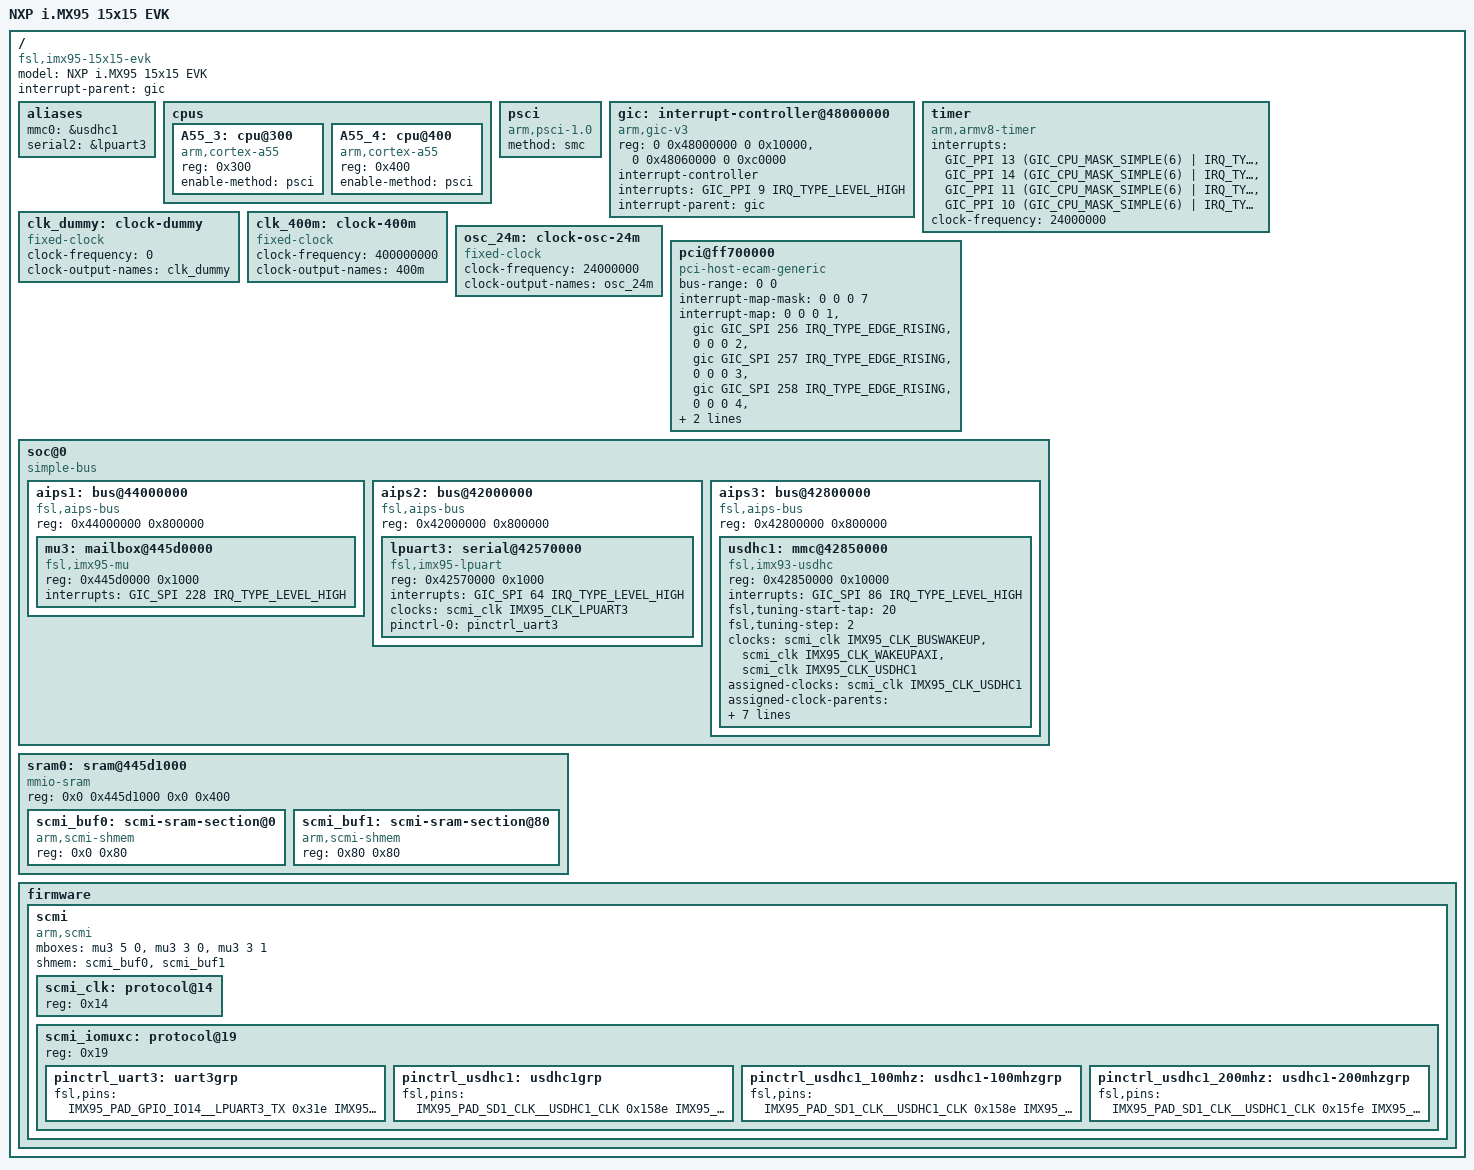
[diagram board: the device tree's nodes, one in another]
// SPDX-License-Identifier: (GPL-2.0+ OR MIT)
/*
 * Copyright 2024 NXP
 */

/dts-v1/;

#include <dt-bindings/clock/fsl,imx95-clock.h>
#include <dt-bindings/interrupt-controller/arm-gic.h>
#include "imx95-pinfunc.h"

/ {
	model = "NXP i.MX95 15x15 EVK";
	compatible = "fsl,imx95-15x15-evk", "fsl,imx95";
	interrupt-parent = <&gic>;
	#address-cells = <2>;
	#size-cells = <2>;

	aliases {
		mmc0 = &usdhc1;
		serial2 = &lpuart3;
	};

	cpus {
		#address-cells = <1>;
		#size-cells = <0>;

		A55_3: cpu@300 {
			device_type = "cpu";
			compatible = "arm,cortex-a55";
			reg = <0x300>;
			enable-method = "psci";
			#cooling-cells = <2>;
		};

		A55_4: cpu@400 {
			device_type = "cpu";
			compatible = "arm,cortex-a55";
			reg = <0x400>;
			enable-method = "psci";
			#cooling-cells = <2>;
		};
	};

	psci {
		compatible = "arm,psci-1.0";
		method = "smc";
	};

	gic: interrupt-controller@48000000 {
		compatible = "arm,gic-v3";
		reg = <0 0x48000000 0 0x10000>,
		      <0 0x48060000 0 0xc0000>;
		#interrupt-cells = <3>;
		interrupt-controller;
		interrupts = <GIC_PPI 9 IRQ_TYPE_LEVEL_HIGH>;
		interrupt-parent = <&gic>;
	};

	timer {
		compatible = "arm,armv8-timer";
		interrupts = <GIC_PPI 13 (GIC_CPU_MASK_SIMPLE(6) | IRQ_TYPE_LEVEL_LOW)>,
			     <GIC_PPI 14 (GIC_CPU_MASK_SIMPLE(6) | IRQ_TYPE_LEVEL_LOW)>,
			     <GIC_PPI 11 (GIC_CPU_MASK_SIMPLE(6) | IRQ_TYPE_LEVEL_LOW)>,
			     <GIC_PPI 10 (GIC_CPU_MASK_SIMPLE(6) | IRQ_TYPE_LEVEL_LOW)>;
		clock-frequency = <24000000>;
	};

	clk_dummy: clock-dummy {
		compatible = "fixed-clock";
		#clock-cells = <0>;
		clock-frequency = <0>;
		clock-output-names = "clk_dummy";
	};

	clk_400m: clock-400m {
		compatible = "fixed-clock";
		#clock-cells = <0>;
		clock-frequency = <400000000>;
		clock-output-names = "400m";
	};

	osc_24m: clock-osc-24m {
		compatible = "fixed-clock";
		#clock-cells = <0>;
		clock-frequency = <24000000>;
		clock-output-names = "osc_24m";
	};

	pci@ff700000 {
		compatible = "pci-host-ecam-generic";
		device_type = "pci";
		bus-range = <0 0>;
		#address-cells = <3>;
		#size-cells = <2>;
		#interrupt-cells = <1>;
		interrupt-map-mask = <0 0 0 7>;
		interrupt-map = <0 0 0 1 &gic GIC_SPI 256 IRQ_TYPE_EDGE_RISING>,
				<0 0 0 2 &gic GIC_SPI 257 IRQ_TYPE_EDGE_RISING>,
				<0 0 0 3 &gic GIC_SPI 258 IRQ_TYPE_EDGE_RISING>,
				<0 0 0 4 &gic GIC_SPI 259 IRQ_TYPE_EDGE_RISING>;
		reg = <0x0 0xff700000 0x0 0x100000>;
		ranges = <0x02000000 0x00 0x10000000 0x0 0x10000000 0x00 0x10000>;
	};

	soc@0 {
		compatible = "simple-bus";
		#address-cells = <1>;
		#size-cells = <1>;
		ranges = <0x0 0x0 0x0 0x80000000>,
			 <0x28000000 0x0 0x28000000 0x10000000>;

		aips1: bus@44000000 {
			compatible = "fsl,aips-bus", "simple-bus";
			reg = <0x44000000 0x800000>;
			#address-cells = <1>;
			#size-cells = <1>;
			ranges;

			mu3: mailbox@445d0000 {
				compatible = "fsl,imx95-mu", "fsl,imx8ulp-mu";
				reg = <0x445d0000 0x1000>;
				interrupts = <GIC_SPI 228 IRQ_TYPE_LEVEL_HIGH>;
				#mbox-cells = <2>;
				status = "okay";
			};
		};

		aips2: bus@42000000 {
			compatible = "fsl,aips-bus", "simple-bus";
			reg = <0x42000000 0x800000>;
			#address-cells = <1>;
			#size-cells = <1>;
			ranges;

			lpuart3: serial@42570000 {
				compatible = "fsl,imx95-lpuart", "fsl,imx8ulp-lpuart",
					     "fsl,imx7ulp-lpuart";
				reg = <0x42570000 0x1000>;
				interrupts = <GIC_SPI 64 IRQ_TYPE_LEVEL_HIGH>;
				clock-names = "ipg";
				status = "disabled";
			};
		};

		aips3: bus@42800000 {
			compatible = "fsl,aips-bus", "simple-bus";
			reg = <0x42800000 0x800000>;
			#address-cells = <1>;
			#size-cells = <1>;
			ranges;

			usdhc1: mmc@42850000 {
				compatible = "fsl,imx93-usdhc", "fsl,imx8mm-usdhc";
				reg = <0x42850000 0x10000>;
				interrupts = <GIC_SPI 86 IRQ_TYPE_LEVEL_HIGH>;
				fsl,tuning-start-tap = <20>;
				fsl,tuning-step= <2>;
				status = "disabled";
			};
		};
	};

	sram0: sram@445d1000 {
		compatible = "mmio-sram";
		reg = <0x0 0x445d1000 0x0 0x400>;
		#address-cells = <1>;
		#size-cells = <1>;
		ranges = <0x0 0x0 0x445d1000 0x400>;

		scmi_buf0: scmi-sram-section@0 {
			compatible = "arm,scmi-shmem";
			reg = <0x0 0x80>;
		};

		scmi_buf1: scmi-sram-section@80 {
			compatible = "arm,scmi-shmem";
			reg = <0x80 0x80>;
		};
	};

	firmware {
		scmi {
			compatible = "arm,scmi";
			mboxes = <&mu3 5 0>, <&mu3 3 0>, <&mu3 3 1>;
			shmem = <&scmi_buf0>, <&scmi_buf1>;
			#address-cells = <1>;
			#size-cells = <0>;

			scmi_clk: protocol@14 {
				reg = <0x14>;
				#clock-cells = <1>;
			};

			scmi_iomuxc: protocol@19 {
				reg = <0x19>;
			};
		};
	};
};

&lpuart3 {
	clocks = <&scmi_clk IMX95_CLK_LPUART3>;
	pinctrl-names = "default";
	pinctrl-0 = <&pinctrl_uart3>;
	status = "okay";
};

&usdhc1 {
	clocks = <&scmi_clk IMX95_CLK_BUSWAKEUP>,
		 <&scmi_clk IMX95_CLK_WAKEUPAXI>,
		 <&scmi_clk IMX95_CLK_USDHC1>;
	clock-names = "ipg", "ahb", "per";
	assigned-clocks = <&scmi_clk IMX95_CLK_USDHC1>;
	assigned-clock-parents = <&scmi_clk IMX95_CLK_SYSPLL1_PFD1>;
	assigned-clock-rates = <400000000>;
	pinctrl-names = "default", "state_100mhz", "state_200mhz";
	pinctrl-0 = <&pinctrl_usdhc1>;
	pinctrl-1 = <&pinctrl_usdhc1_100mhz>;
	pinctrl-2 = <&pinctrl_usdhc1_200mhz>;
	bus-width = <8>;
	non-removable;
	status = "okay";
};

&scmi_iomuxc {
	pinctrl_uart3: uart3grp {
		fsl,pins = <
			IMX95_PAD_GPIO_IO14__LPUART3_TX      0x31e
			IMX95_PAD_GPIO_IO15__LPUART3_RX      0x31e
		>;
	};

	pinctrl_usdhc1: usdhc1grp {
		fsl,pins = <
			IMX95_PAD_SD1_CLK__USDHC1_CLK				0x158e
			IMX95_PAD_SD1_CMD__USDHC1_CMD				0x138e
			IMX95_PAD_SD1_DATA0__USDHC1_DATA0			0x138e
			IMX95_PAD_SD1_DATA1__USDHC1_DATA1			0x138e
			IMX95_PAD_SD1_DATA2__USDHC1_DATA2			0x138e
			IMX95_PAD_SD1_DATA3__USDHC1_DATA3			0x138e
			IMX95_PAD_SD1_DATA4__USDHC1_DATA4			0x138e
			IMX95_PAD_SD1_DATA5__USDHC1_DATA5			0x138e
			IMX95_PAD_SD1_DATA6__USDHC1_DATA6			0x138e
			IMX95_PAD_SD1_DATA7__USDHC1_DATA7			0x138e
			IMX95_PAD_SD1_STROBE__USDHC1_STROBE			0x158e
		>;
	};

	pinctrl_usdhc1_100mhz: usdhc1-100mhzgrp {
		fsl,pins = <
			IMX95_PAD_SD1_CLK__USDHC1_CLK				0x158e
			IMX95_PAD_SD1_CMD__USDHC1_CMD				0x138e
			IMX95_PAD_SD1_DATA0__USDHC1_DATA0			0x138e
			IMX95_PAD_SD1_DATA1__USDHC1_DATA1			0x138e
			IMX95_PAD_SD1_DATA2__USDHC1_DATA2			0x138e
			IMX95_PAD_SD1_DATA3__USDHC1_DATA3			0x138e
			IMX95_PAD_SD1_DATA4__USDHC1_DATA4			0x138e
			IMX95_PAD_SD1_DATA5__USDHC1_DATA5			0x138e
			IMX95_PAD_SD1_DATA6__USDHC1_DATA6			0x138e
			IMX95_PAD_SD1_DATA7__USDHC1_DATA7			0x138e
			IMX95_PAD_SD1_STROBE__USDHC1_STROBE			0x158e
		>;
	};

	pinctrl_usdhc1_200mhz: usdhc1-200mhzgrp {
		fsl,pins = <
			IMX95_PAD_SD1_CLK__USDHC1_CLK				0x15fe
			IMX95_PAD_SD1_CMD__USDHC1_CMD				0x13fe
			IMX95_PAD_SD1_DATA0__USDHC1_DATA0			0x13fe
			IMX95_PAD_SD1_DATA1__USDHC1_DATA1			0x13fe
			IMX95_PAD_SD1_DATA2__USDHC1_DATA2			0x13fe
			IMX95_PAD_SD1_DATA3__USDHC1_DATA3			0x13fe
			IMX95_PAD_SD1_DATA4__USDHC1_DATA4			0x13fe
			IMX95_PAD_SD1_DATA5__USDHC1_DATA5			0x13fe
			IMX95_PAD_SD1_DATA6__USDHC1_DATA6			0x13fe
			IMX95_PAD_SD1_DATA7__USDHC1_DATA7			0x13fe
			IMX95_PAD_SD1_STROBE__USDHC1_STROBE			0x15fe
		>;
	};
};
